# AT90USB1287 register map
Vendor: Atmel; File version: 1.0
CPU: other r0p0, little endian, no MPU, no FPU, 4 interrupt priority bits
Registers are 8-bit, read-write, reset 0x0 unless marked. A register's access mark holds for its fields unless they carry their own. Offsets are from the block's base; [hi:lo] are bit positions.

## TC3 — Timer/Counter, 16-bit
Base 0x00000038
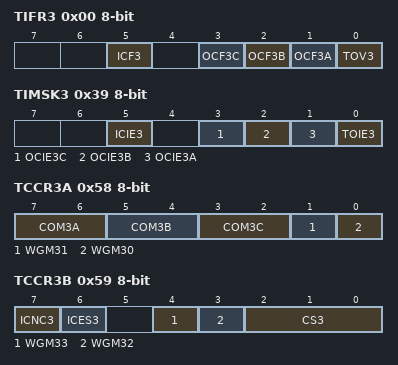
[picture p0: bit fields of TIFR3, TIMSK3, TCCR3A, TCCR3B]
0x00 TIFR3 — Timer/Counter3 Interrupt Flag register
  [5] ICF3 — Input Capture Flag 3
  [3] OCF3C — Output Compare Flag 3C
  [2] OCF3B — Output Compare Flag 3B
  [1] OCF3A — Output Compare Flag 3A
  [0] TOV3 — Timer/Counter3 Overflow Flag
0x39 TIMSK3 — Timer/Counter3 Interrupt Mask Register
  [5] ICIE3 — Timer/Counter3 Input Capture Interrupt Enable
  [3] OCIE3C — Timer/Counter3 Output Compare C Match Interrupt Enable
  [2] OCIE3B — Timer/Counter3 Output Compare B Match Interrupt Enable
  [1] OCIE3A — Timer/Counter3 Output Compare A Match Interrupt Enable
  [0] TOIE3 — Timer/Counter3 Overflow Interrupt Enable
0x58 TCCR3A — Timer/Counter3 Control Register A
  [7:6] COM3A — Compare Output Mode 1A, bits
  [5:4] COM3B — Compare Output Mode 3B, bits
  [3:2] COM3C — Compare Output Mode 3C, bits
  [1] WGM31 — Waveform Generation Mode
  [0] WGM30 — Waveform Generation Mode
0x59 TCCR3B — Timer/Counter3 Control Register B
  [7] ICNC3 — Input Capture 3 Noise Canceler
  [6] ICES3 — Input Capture 3 Edge Select
  [4] WGM33 — Waveform Generation Mode
  [3] WGM32 — Waveform Generation Mode
  [2:0] CS3 — Prescaler source of Timer/Counter 3
    0=No Clock Source (Stopped); 1=Running, No Prescaling; 2=Running, CLK/8; 3=Running, CLK/64; 4=Running, CLK/256; 5=Running, CLK/1024; 6=Running, ExtClk Tx Falling Edge; 7=Running, ExtClk Tx Rising Edge
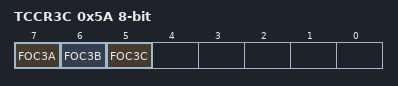
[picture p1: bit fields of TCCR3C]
0x5A TCCR3C — Timer/Counter 3 Control Register C
  [7] FOC3A — Force Output Compare 3A
  [6] FOC3B — Force Output Compare 3B
  [5] FOC3C — Force Output Compare 3C
0x5C TCNT3 16-bit (reset mask 0xFF) — Timer/Counter3 Bytes
0x5E ICR3 16-bit (reset mask 0xFF) — Timer/Counter3 Input Capture Register Bytes
0x60 OCR3A 16-bit (reset mask 0xFF) — Timer/Counter3 Output Compare Register A Bytes
0x62 OCR3B 16-bit (reset mask 0xFF) — Timer/Counter3 Output Compare Register B Bytes
0x64 OCR3C 16-bit (reset mask 0xFF) — Timer/Counter3 Output Compare Register B Bytes

## TWI — Two Wire Serial Interface
Base 0x000000B8
0x00 TWBR — TWI Bit Rate register
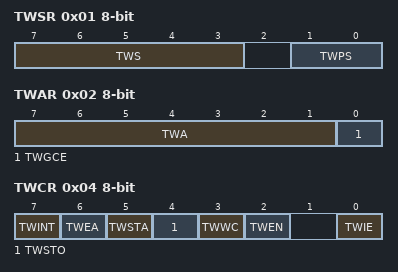
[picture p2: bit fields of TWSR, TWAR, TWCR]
0x01 TWSR — TWI Status Register
  [7:3] TWS — TWI Status
  [1:0] TWPS — TWI Prescaler
    0=1; 1=4; 2=16; 3=64
0x02 TWAR — TWI (Slave) Address register
  [7:1] TWA — TWI (Slave) Address register Bits
  [0] TWGCE — TWI General Call Recognition Enable Bit
0x03 TWDR — TWI Data register
0x04 TWCR — TWI Control Register
  [7] TWINT — TWI Interrupt Flag
  [6] TWEA — TWI Enable Acknowledge Bit
  [5] TWSTA — TWI Start Condition Bit
  [4] TWSTO — TWI Stop Condition Bit
  [3] TWWC — TWI Write Collition Flag
  [2] TWEN — TWI Enable Bit
  [0] TWIE — TWI Interrupt Enable
0x05 TWAMR — TWI (Slave) Address Mask Register
  [7:1] TWAM

## USART1 — USART
Base 0x000000C8
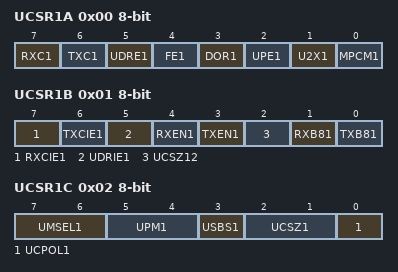
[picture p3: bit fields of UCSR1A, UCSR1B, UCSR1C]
0x00 UCSR1A — USART Control and Status Register A
  [7] RXC1 — USART Receive Complete
  [6] TXC1 — USART Transmitt Complete
  [5] UDRE1 — USART Data Register Empty
  [4] FE1 — Framing Error
  [3] DOR1 — Data overRun
  [2] UPE1 — Parity Error
  [1] U2X1 — Double the USART transmission speed
  [0] MPCM1 — Multi-processor Communication Mode
0x01 UCSR1B — USART Control and Status Register B
  [7] RXCIE1 — RX Complete Interrupt Enable
  [6] TXCIE1 — TX Complete Interrupt Enable
  [5] UDRIE1 — USART Data register Empty Interrupt Enable
  [4] RXEN1 — Receiver Enable
  [3] TXEN1 — Transmitter Enable
  [2] UCSZ12 — Character Size
  [1] RXB81 — Receive Data Bit 8
  [0] TXB81 — Transmit Data Bit 8
0x02 UCSR1C — USART Control and Status Register C
  [7:6] UMSEL1 — USART Mode Select
    0=Asynchronous USART; 1=Synchronous USART; 3=Master SPI
  [5:4] UPM1 — Parity Mode Bits
    0=Disabled; 2=Enabled, Even Parity; 3=Enabled, Odd Parity
  [3] USBS1 — Stop Bit Select
    0=1-bit; 1=2-bit
  [2:1] UCSZ1 — Character Size
  [0] UCPOL1 — Clock Polarity
0x04 UBRR1 16-bit (reset mask 0xFF) — USART Baud Rate Register Bytes
0x06 UDR1 — USART I/O Data Register

## USB_DEVICE — USB Device Registers
Base 0x000000E0
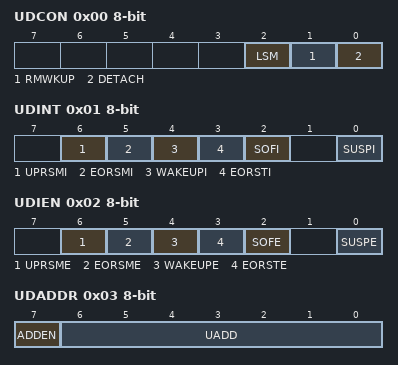
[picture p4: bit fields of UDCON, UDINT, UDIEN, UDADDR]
0x00 UDCON
  [2] LSM, [1] RMWKUP, [0] DETACH
0x01 UDINT
  [6] UPRSMI, [5] EORSMI, [4] WAKEUPI, [3] EORSTI, [2] SOFI, [0] SUSPI
0x02 UDIEN
  [6] UPRSME, [5] EORSME, [4] WAKEUPE, [3] EORSTE, [2] SOFE, [0] SUSPE
0x03 UDADDR
  [7] ADDEN, [6:0] UADD
0x04 UDFNUM 16-bit (reset mask 0xFF)
0x06 UDMFN
  [4] FNCERR
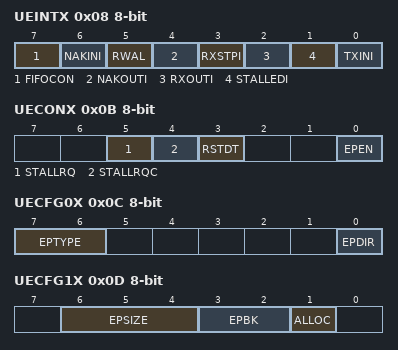
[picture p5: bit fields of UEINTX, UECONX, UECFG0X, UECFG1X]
0x08 UEINTX
  [7] FIFOCON, [6] NAKINI, [5] RWAL, [4] NAKOUTI, [3] RXSTPI, [2] RXOUTI, [1] STALLEDI, [0] TXINI
0x09 UENUM
0x0A UERST
  [6:0] EPRST
0x0B UECONX
  [5] STALLRQ, [4] STALLRQC, [3] RSTDT, [0] EPEN
0x0C UECFG0X
  [7:6] EPTYPE, [0] EPDIR
0x0D UECFG1X
  [6:4] EPSIZE, [3:2] EPBK, [1] ALLOC
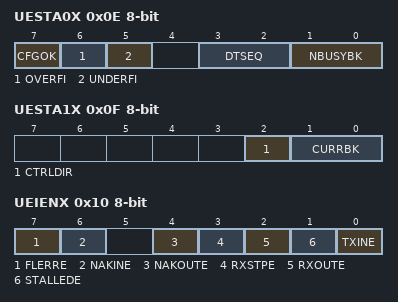
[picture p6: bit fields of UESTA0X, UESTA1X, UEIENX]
0x0E UESTA0X
  [7] CFGOK, [6] OVERFI, [5] UNDERFI, [3:2] DTSEQ, [1:0] NBUSYBK
0x0F UESTA1X
  [2] CTRLDIR, [1:0] CURRBK
0x10 UEIENX
  [7] FLERRE, [6] NAKINE, [4] NAKOUTE, [3] RXSTPE, [2] RXOUTE, [1] STALLEDE, [0] TXINE
0x11 UEDATX
0x12 UEBCLX
0x13 UEBCHX
0x14 UEINT

## USB_GLOBAL — USB Controller
Base 0x000000D7
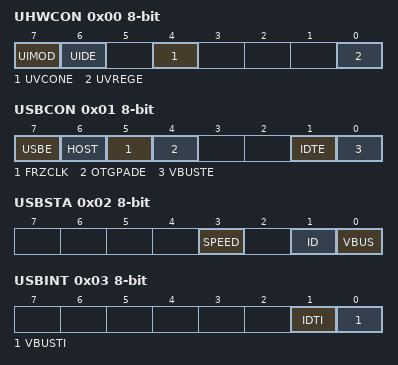
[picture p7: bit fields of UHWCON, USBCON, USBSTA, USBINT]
0x00 UHWCON — USB Hardware Configuration Register
  [7] UIMOD, [6] UIDE, [4] UVCONE, [0] UVREGE
0x01 USBCON — USB General Control Register
  [7] USBE, [6] HOST, [5] FRZCLK, [4] OTGPADE, [1] IDTE, [0] VBUSTE
0x02 USBSTA
  [3] SPEED, [1] ID, [0] VBUS
0x03 USBINT
  [1] IDTI, [0] VBUSTI
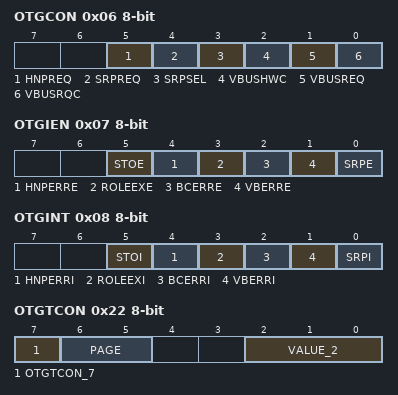
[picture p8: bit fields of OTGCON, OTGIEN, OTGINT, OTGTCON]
0x06 OTGCON
  [5] HNPREQ, [4] SRPREQ, [3] SRPSEL, [2] VBUSHWC, [1] VBUSREQ, [0] VBUSRQC
0x07 OTGIEN
  [5] STOE, [4] HNPERRE, [3] ROLEEXE, [2] BCERRE, [1] VBERRE, [0] SRPE
0x08 OTGINT
  [5] STOI, [4] HNPERRI, [3] ROLEEXI, [2] BCERRI, [1] VBERRI, [0] SRPI
0x22 OTGTCON
  [7] OTGTCON_7, [6:5] PAGE, [2:0] VALUE_2

## USB_HOST — USB Host Registers
Base 0x0000009E
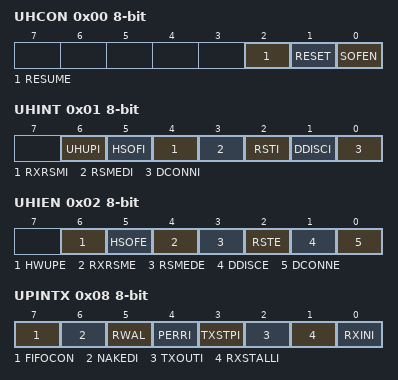
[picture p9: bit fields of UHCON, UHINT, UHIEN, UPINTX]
0x00 UHCON
  [2] RESUME, [1] RESET, [0] SOFEN
0x01 UHINT
  [6] UHUPI, [5] HSOFI, [4] RXRSMI, [3] RSMEDI, [2] RSTI, [1] DDISCI, [0] DCONNI
0x02 UHIEN
  [6] HWUPE, [5] HSOFE, [4] RXRSME, [3] RSMEDE, [2] RSTE, [1] DDISCE, [0] DCONNE
0x03 UHADDR
0x04 UHFNUM 16-bit (reset mask 0xFF)
0x06 UHFLEN
0x07 UPINRQX
0x08 UPINTX
  [7] FIFOCON, [6] NAKEDI, [5] RWAL, [4] PERRI, [3] TXSTPI, [2] TXOUTI, [1] RXSTALLI, [0] RXINI
0x09 UPNUM
0x0A UPRST
  [6:0] PRST
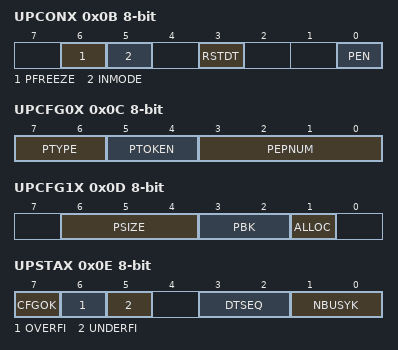
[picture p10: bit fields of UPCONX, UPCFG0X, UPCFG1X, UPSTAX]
0x0B UPCONX
  [6] PFREEZE, [5] INMODE, [3] RSTDT, [0] PEN
0x0C UPCFG0X
  [7:6] PTYPE, [5:4] PTOKEN, [3:0] PEPNUM
0x0D UPCFG1X
  [6:4] PSIZE, [3:2] PBK, [1] ALLOC
0x0E UPSTAX
  [7] CFGOK, [6] OVERFI, [5] UNDERFI, [3:2] DTSEQ, [1:0] NBUSYK
0x0F UPCFG2X
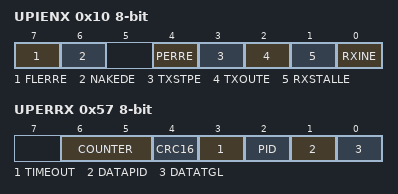
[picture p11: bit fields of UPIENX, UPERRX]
0x10 UPIENX
  [7] FLERRE, [6] NAKEDE, [4] PERRE, [3] TXSTPE, [2] TXOUTE, [1] RXSTALLE, [0] RXINE
0x11 UPDATX
0x57 UPERRX
  [6:5] COUNTER, [4] CRC16, [3] TIMEOUT, [2] PID, [1] DATAPID, [0] DATATGL
0x58 UPBCLX
0x59 UPBCHX
0x5A UPINT

## WDT — Watchdog Timer
Base 0x00000060
0x00 WDTCSR — Watchdog Timer Control Register
  [7] WDIF — Watchdog Timeout Interrupt Flag
  [6] WDIE — Watchdog Timeout Interrupt Enable
  [4] WDCE — Watchdog Change Enable
  [3] WDE — Watch Dog Enable
  [5:0] WDP — Watchdog Timer Prescaler Bits
    0=Oscillator Cycles 2K; 1=Oscillator Cycles 4K; 2=Oscillator Cycles 8K; 3=Oscillator Cycles 16K; 4=Oscillator Cycles 32K; 5=Oscillator Cycles 64K; 6=Oscillator Cycles 128K; 7=Oscillator Cycles 256K
